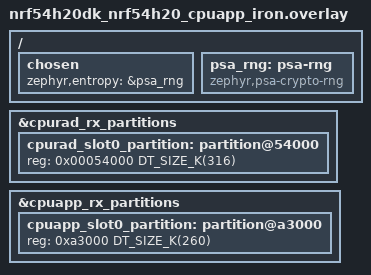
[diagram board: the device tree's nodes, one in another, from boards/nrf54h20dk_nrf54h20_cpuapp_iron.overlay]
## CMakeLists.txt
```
#
# Copyright (c) 2024 Nordic Semiconductor
#
# SPDX-License-Identifier: LicenseRef-Nordic-5-Clause
#

cmake_minimum_required(VERSION 3.20.0)

find_package(Zephyr REQUIRED HINTS $ENV{ZEPHYR_BASE})
project(channel_sound_ras_initiator)

FILE(GLOB app_sources src/*.c)
# NORDIC SDK APP START
target_sources(app PRIVATE
  ${app_sources}
)
# NORDIC SDK APP END
```

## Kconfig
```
#
# Copyright (c) 2024 Nordic Semiconductor ASA
#
# SPDX-License-Identifier: LicenseRef-Nordic-5-Clause
#

mainmenu "Nordic Channel Sounding RAS Initiator sample"

choice CS_TONE_ANTENNA_CONFIGURATION
	prompt "Tone antenna configuration selection"
	default CS_TONE_ANTENNA_CONFIGURATION_A1_B1
	help
	  Select the tone antenna configuration for channel sounding procedures.
	  The configuration determines how many antenna paths are used on each side
	  (initiator and reflector). The format is A<initiator_antennas>_B<reflector_antennas>.

config CS_TONE_ANTENNA_CONFIGURATION_A1_B1
	bool "A1_B1 (1 antenna path per side)"
	help
	  Use A1_B1 configuration with 1 antenna path on each side.
	  This requires BT_CTLR_SDC_CS_MAX_ANTENNA_PATHS >= 1.

config CS_TONE_ANTENNA_CONFIGURATION_A2_B1
	bool "A2_B1 (2 initiator, 1 reflector antenna paths)"
	help
	  Use A2_B1 configuration with 2 antenna paths on initiator side and
	  1 antenna path on reflector side.
	  This requires BT_CTLR_SDC_CS_MAX_ANTENNA_PATHS >= 2.

config CS_TONE_ANTENNA_CONFIGURATION_A3_B1
	bool "A3_B1 (3 initiator, 1 reflector antenna paths)"
	help
	  Use A3_B1 configuration with 3 antenna paths on initiator side and
	  1 antenna path on reflector side.
	  This requires BT_CTLR_SDC_CS_MAX_ANTENNA_PATHS >= 3.

config CS_TONE_ANTENNA_CONFIGURATION_A4_B1
	bool "A4_B1 (4 initiator, 1 reflector antenna paths)"
	help
	  Use A4_B1 configuration with 4 antenna paths on initiator side and
	  1 antenna path on reflector side.
	  This requires BT_CTLR_SDC_CS_MAX_ANTENNA_PATHS >= 4.

config CS_TONE_ANTENNA_CONFIGURATION_A1_B2
	bool "A1_B2 (1 initiator, 2 reflector antenna paths)"
	help
	  Use A1_B2 configuration with 1 antenna path on initiator side and
	  2 antenna paths on reflector side.
	  This requires BT_CTLR_SDC_CS_MAX_ANTENNA_PATHS >= 2.

config CS_TONE_ANTENNA_CONFIGURATION_A1_B3
	bool "A1_B3 (1 initiator, 3 reflector antenna paths)"
	help
	  Use A1_B3 configuration with 1 antenna path on initiator side and
	  3 antenna paths on reflector side.
	  This requires BT_CTLR_SDC_CS_MAX_ANTENNA_PATHS >= 3.

config CS_TONE_ANTENNA_CONFIGURATION_A1_B4
	bool "A1_B4 (1 initiator, 4 reflector antenna paths)"
	help
	  Use A1_B4 configuration with 1 antenna path on initiator side and
	  4 antenna paths on reflector side.
	  This requires BT_CTLR_SDC_CS_MAX_ANTENNA_PATHS >= 4.

config CS_TONE_ANTENNA_CONFIGURATION_A2_B2
	bool "A2_B2 (2 antenna paths per side)"
	help
	  Use A2_B2 configuration with 2 antenna paths on each side (4 total).
	  This requires BT_CTLR_SDC_CS_MAX_ANTENNA_PATHS >= 4.

endchoice

config CS_TONE_ANTENNA_CONFIGURATION_VALUE
	int
	default 0 if CS_TONE_ANTENNA_CONFIGURATION_A1_B1
	default 1 if CS_TONE_ANTENNA_CONFIGURATION_A2_B1
	default 2 if CS_TONE_ANTENNA_CONFIGURATION_A3_B1
	default 3 if CS_TONE_ANTENNA_CONFIGURATION_A4_B1
	default 4 if CS_TONE_ANTENNA_CONFIGURATION_A1_B2
	default 5 if CS_TONE_ANTENNA_CONFIGURATION_A1_B3
	default 6 if CS_TONE_ANTENNA_CONFIGURATION_A1_B4
	default 7 if CS_TONE_ANTENNA_CONFIGURATION_A2_B2
	help
	  Internal config value mapping to BT_LE_CS_TONE_ANTENNA_CONFIGURATION enum.
	  Not intended for direct use.

# Intermediate config: number of antenna paths required for the selected configuration
# This is the maximum number of antenna paths needed on either the initiator or reflector side
config CS_TONE_ANTENNA_CONFIGURATION_NUM_ANTENNA_PATHS
	int
	default 1 if CS_TONE_ANTENNA_CONFIGURATION_A1_B1
	default 2 if CS_TONE_ANTENNA_CONFIGURATION_A2_B1 || CS_TONE_ANTENNA_CONFIGURATION_A1_B2
	default 3 if CS_TONE_ANTENNA_CONFIGURATION_A3_B1 || CS_TONE_ANTENNA_CONFIGURATION_A1_B3
	default 4 if CS_TONE_ANTENNA_CONFIGURATION_A4_B1 || CS_TONE_ANTENNA_CONFIGURATION_A1_B4 || CS_TONE_ANTENNA_CONFIGURATION_A2_B2
	help
	  Number of antenna paths required for the selected tone antenna configuration.
	  This is calculated as the maximum number of antenna paths needed on either
	  the initiator or reflector side.

# Set default value for BT_CTLR_SDC_CS_MAX_ANTENNA_PATHS based on the required number of antenna paths
# This ensures the controller is configured with sufficient antenna paths for the selected configuration
if BT_CTLR_CHANNEL_SOUNDING
config BT_CTLR_SDC_CS_MAX_ANTENNA_PATHS
	default CS_TONE_ANTENNA_CONFIGURATION_NUM_ANTENNA_PATHS
endif

source "Kconfig.zephyr"
```

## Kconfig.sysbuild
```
#
# Copyright (c) 2025 Nordic Semiconductor
#
# SPDX-License-Identifier: LicenseRef-Nordic-5-Clause
#

source "share/sysbuild/Kconfig"

config NRF_DEFAULT_BLUETOOTH
	default y

config NETCORE_IPC_RADIO_BT_HCI_IPC
	default y
```

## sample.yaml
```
sample:
  description: Bluetooth Low Energy Channel Sounding Initiator with Ranging Service
    Requestor
  name: Bluetooth LE Channel Sounding Initiator with RREQ
tests:
  sample.bluetooth.channel_sounding_ras_initiator:
    sysbuild: true
    build_only: true
    integration_platforms:
      - nrf54h20dk/nrf54h20/cpuapp
      - nrf54l15dk/nrf54l15/cpuapp
    platform_allow:
      - nrf54l15dk/nrf54l05/cpuapp
      - nrf54l15dk/nrf54l10/cpuapp
      - nrf54l15dk/nrf54l15/cpuapp
      - nrf54h20dk/nrf54h20/cpuapp
      - nrf54lm20dk/nrf54lm20a/cpuapp
      - nrf54lv10dk/nrf54lv10a/cpuapp
      - nrf54lv10dk/nrf54lv10a/cpuapp/ns
    tags:
      - bluetooth
      - ci_build
      - sysbuild
```

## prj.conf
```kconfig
#
# Copyright (c) 2024 Nordic Semiconductor ASA
#
# SPDX-License-Identifier: LicenseRef-Nordic-5-Clause
#

CONFIG_NCS_SAMPLES_DEFAULTS=y
CONFIG_DK_LIBRARY=y

CONFIG_BT=y
CONFIG_BT_SMP=y
CONFIG_BT_CENTRAL=y
CONFIG_BT_MAX_CONN=1
CONFIG_BT_BONDABLE=n

CONFIG_BT_GATT_CLIENT=y
CONFIG_BT_GATT_DYNAMIC_DB=y

CONFIG_BT_CHANNEL_SOUNDING=y
CONFIG_BT_RAS=y
CONFIG_BT_RAS_RREQ=y

CONFIG_BT_SCAN=y
CONFIG_BT_SCAN_FILTER_ENABLE=y
CONFIG_BT_SCAN_UUID_CNT=1

# The Ranging Profile recommends a MTU of at least 247 octets.
CONFIG_BT_L2CAP_TX_MTU=498
CONFIG_BT_BUF_ACL_TX_SIZE=502
CONFIG_BT_BUF_ACL_RX_SIZE=502
CONFIG_BT_ATT_PREPARE_COUNT=3
CONFIG_BT_CTLR_DATA_LENGTH_MAX=251

# This reduces RAM usage. Additional RAM is needed to support optional
# features such as mode 3 or multiantenna. Change or remove these if
# using those features
CONFIG_BT_RAS_MODE_3_SUPPORTED=n
CONFIG_BT_RAS_MAX_ANTENNA_PATHS=1
CONFIG_BT_CTLR_SDC_CS_MAX_ANTENNA_PATHS=1
CONFIG_BT_CTLR_SDC_CS_NUM_ANTENNAS=1
CONFIG_BT_CTLR_SDC_CS_STEP_MODE3=n
CONFIG_BT_CTLR_SDC_CS_ROLE_INITIATOR_ONLY=y

# Disabling the CS Test command reduces flash usage
CONFIG_BT_CTLR_CHANNEL_SOUNDING_TEST=n

# This allows CS and ACL to use different PHYs
CONFIG_BT_TRANSMIT_POWER_CONTROL=y

# This improves the performance of floating-point operations
CONFIG_FPU=y
CONFIG_FPU_SHARING=y

CONFIG_CBPRINTF_FP_SUPPORT=y

CONFIG_BT_CS_DE=y
CONFIG_BT_CS_DE_512_NFFT=y
CONFIG_CS_TONE_ANTENNA_CONFIGURATION_A4_B1=y
```

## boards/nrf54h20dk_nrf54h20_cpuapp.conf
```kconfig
#
# Copyright (c) 2025 Nordic Semiconductor
#
# SPDX-License-Identifier: LicenseRef-Nordic-5-Clause
#

CONFIG_BT_RX_STACK_SIZE=2048

# Enable PSA RNG
CONFIG_PSA_CRYPTO_DRIVER_OBERON=n
CONFIG_PSA_SSF_CRYPTO_CLIENT=y
CONFIG_SSF_PSA_CRYPTO_SERVICE_ENABLED=y
CONFIG_MBEDTLS_PSA_CRYPTO_C=y
CONFIG_NRF_SECURITY=y
```

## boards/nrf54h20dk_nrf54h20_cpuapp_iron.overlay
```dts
/*
 * Copyright (c) 2025 Nordic Semiconductor ASA
 *
 * SPDX-License-Identifier: LicenseRef-Nordic-5-Clause
 */

/delete-node/ &cpuapp_slot0_partition;
/delete-node/ &cpurad_slot0_partition;

/* Allocate extra MRAM as 256K is not enough NVM for multiantenna CS.
 * The extra memory is taken from cpuapp below.
 */
&cpurad_rx_partitions {
	cpurad_slot0_partition: partition@54000 {
		reg = <0x00054000 DT_SIZE_K(316)>;
	};
};

/* Reduce cpuapp by 60K (default 320 - 60) */
&cpuapp_rx_partitions {
	cpuapp_slot0_partition: partition@a3000 {
		reg = <0xa3000 DT_SIZE_K(260)>;
	};
};

// Enable PSA RNG
/ {
	chosen {
		zephyr,entropy = &psa_rng;
	};

	psa_rng: psa-rng {
		compatible = "zephyr,psa-crypto-rng";
		status = "okay";
	};

	/delete-node/ prng;
};
```

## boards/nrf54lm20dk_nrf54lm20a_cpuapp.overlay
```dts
/*
 * Copyright (c) 2025 Nordic Semiconductor ASA
 *
 * SPDX-License-Identifier: LicenseRef-Nordic-5-Clause
 */

/ {
	cs_antenna_switch: cs-antenna-config {
		status = "okay";
		compatible = "nordic,bt-cs-antenna-switch";
		ant-gpios = <&gpio1 17 GPIO_ACTIVE_HIGH>,
			    <&gpio1 18 GPIO_ACTIVE_HIGH>,
			    <&gpio1 19 GPIO_ACTIVE_HIGH>,
			    <&gpio1 20 GPIO_ACTIVE_HIGH>;
		multiplexing-mode = <0>;
	};
};
```

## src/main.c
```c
/*
 * Copyright (c) 2024 Nordic Semiconductor ASA
 *
 * SPDX-License-Identifier: LicenseRef-Nordic-5-Clause
 */

/** @file
 *  @brief Channel Sounding Initiator with Ranging Requestor sample
 */

#include <math.h>
#include <stdlib.h>
#include <zephyr/kernel.h>
#include <zephyr/types.h>
#include <zephyr/sys/byteorder.h>
#include <zephyr/sys/reboot.h>
#include <zephyr/bluetooth/cs.h>
#include <zephyr/bluetooth/gatt.h>
#include <zephyr/bluetooth/conn.h>
#include <bluetooth/scan.h>
#include <bluetooth/services/ras.h>
#include <bluetooth/gatt_dm.h>
#include <bluetooth/cs_de.h>

#include <dk_buttons_and_leds.h>

#include <zephyr/logging/log.h>
LOG_MODULE_REGISTER(app_main, LOG_LEVEL_INF);

#define CON_STATUS_LED DK_LED1

#define CS_CONFIG_ID	       0
#define NUM_MODE_0_STEPS       3
#define PROCEDURE_COUNTER_NONE (-1)
#define DE_SLIDING_WINDOW_SIZE (9)
#define MAX_AP		       (CONFIG_BT_RAS_MAX_ANTENNA_PATHS)

#define LOCAL_PROCEDURE_MEM                                                                        \
	((BT_RAS_MAX_STEPS_PER_PROCEDURE * sizeof(struct bt_le_cs_subevent_step)) +                \
	 (BT_RAS_MAX_STEPS_PER_PROCEDURE * BT_RAS_MAX_STEP_DATA_LEN))

static K_SEM_DEFINE(sem_remote_capabilities_obtained, 0, 1);
static K_SEM_DEFINE(sem_config_created, 0, 1);
static K_SEM_DEFINE(sem_cs_security_enabled, 0, 1);
static K_SEM_DEFINE(sem_connected, 0, 1);
static K_SEM_DEFINE(sem_discovery_done, 0, 1);
static K_SEM_DEFINE(sem_mtu_exchange_done, 0, 1);
static K_SEM_DEFINE(sem_security, 0, 1);
static K_SEM_DEFINE(sem_ras_features, 0, 1);
static K_SEM_DEFINE(sem_local_steps, 1, 1);
static K_SEM_DEFINE(sem_distance_estimate_updated, 0, 1);

static K_MUTEX_DEFINE(distance_estimate_buffer_mutex);

static struct bt_conn *connection;
NET_BUF_SIMPLE_DEFINE_STATIC(latest_local_steps, LOCAL_PROCEDURE_MEM);
NET_BUF_SIMPLE_DEFINE_STATIC(latest_peer_steps, BT_RAS_PROCEDURE_MEM);
static int32_t most_recent_local_ranging_counter = PROCEDURE_COUNTER_NONE;
static int32_t dropped_ranging_counter = PROCEDURE_COUNTER_NONE;
static uint32_t ras_feature_bits;

static uint8_t buffer_index;
static uint8_t buffer_num_valid;
static cs_de_dist_estimates_t distance_estimate_buffer[MAX_AP][DE_SLIDING_WINDOW_SIZE];
static struct bt_conn_le_cs_config cs_config;

static void store_distance_estimates(cs_de_report_t *p_report)
{
	int lock_state = k_mutex_lock(&distance_estimate_buffer_mutex, K_FOREVER);

	__ASSERT_NO_MSG(lock_state == 0);

	for (uint8_t ap = 0; ap < p_report->n_ap; ap++) {
		memcpy(&distance_estimate_buffer[ap][buffer_index],
		       &p_report->distance_estimates[ap], sizeof(cs_de_dist_estimates_t));
	}

	buffer_index = (buffer_index + 1) % DE_SLIDING_WINDOW_SIZE;

	if (buffer_num_valid < DE_SLIDING_WINDOW_SIZE) {
		buffer_num_valid++;
	}

	k_mutex_unlock(&distance_estimate_buffer_mutex);
}

static int float_cmp(const void *a, const void *b)
{
	float fa = *(const float *)a;
	float fb = *(const float *)b;

	return (fa > fb) - (fa < fb);
}

static float median_inplace(int count, float *values)
{
	if (count == 0) {
		return NAN;
	}

	qsort(values, count, sizeof(float), float_cmp);

	if (count % 2 == 0) {
		return (values[count/2] + values[count/2 - 1]) / 2;
	} else {
		return values[count/2];
	}
}

static cs_de_dist_estimates_t get_distance(uint8_t ap)
{
	cs_de_dist_estimates_t averaged_result = {};
	uint8_t num_ifft = 0;
	uint8_t num_phase_slope = 0;
	uint8_t num_rtt = 0;

	static float temp_ifft[DE_SLIDING_WINDOW_SIZE];
	static float temp_phase_slope[DE_SLIDING_WINDOW_SIZE];
	static float temp_rtt[DE_SLIDING_WINDOW_SIZE];

	int lock_state = k_mutex_lock(&distance_estimate_buffer_mutex, K_FOREVER);

	__ASSERT_NO_MSG(lock_state == 0);

	for (uint8_t i = 0; i < buffer_num_valid; i++) {
		if (isfinite(distance_estimate_buffer[ap][i].ifft)) {
			temp_ifft[num_ifft] = distance_estimate_buffer[ap][i].ifft;
			num_ifft++;
		}
		if (isfinite(distance_estimate_buffer[ap][i].phase_slope)) {
			temp_phase_slope[num_phase_slope] =
				distance_estimate_buffer[ap][i].phase_slope;
			num_phase_slope++;
		}
		if (isfinite(distance_estimate_buffer[ap][i].rtt)) {
			temp_rtt[num_rtt] = distance_estimate_buffer[ap][i].rtt;
			num_rtt++;
		}
	}

	k_mutex_unlock(&distance_estimate_buffer_mutex);

	averaged_result.ifft = median_inplace(num_ifft, temp_ifft);
	averaged_result.phase_slope = median_inplace(num_phase_slope, temp_phase_slope);
	averaged_result.rtt = median_inplace(num_rtt, temp_rtt);

	return averaged_result;
}

static void ranging_data_cb(struct bt_conn *conn, uint16_t ranging_counter, int err)
{
	ARG_UNUSED(conn);

	if (err) {
		LOG_ERR("Error when receiving ranging data with ranging counter %d (err %d)",
			ranging_counter, err);
		return;
	}

	if (ranging_counter != most_recent_local_ranging_counter) {
		LOG_INF("Ranging data dropped as peer ranging counter doesn't match local ranging "
			"data counter. (peer: %u, local: %u)",
			ranging_counter, most_recent_local_ranging_counter);
		net_buf_simple_reset(&latest_local_steps);
		k_sem_give(&sem_local_steps);
		return;
	}

	LOG_DBG("Ranging data received for ranging counter %d", ranging_counter);

	if (latest_local_steps.len == 0) {
		LOG_WRN("All subevents in ranging counter %u were aborted",
			most_recent_local_ranging_counter);
		net_buf_simple_reset(&latest_local_steps);
		k_sem_give(&sem_local_steps);

		if (!(ras_feature_bits & RAS_FEAT_REALTIME_RD)) {
			net_buf_simple_reset(&latest_peer_steps);
		}
		return;
	}

	/* This struct is static to avoid putting it on the stack (it's very large) */
	static cs_de_report_t cs_de_report;

	cs_de_populate_report(&latest_local_steps, &latest_peer_steps, &cs_config, &cs_de_report);

	net_buf_simple_reset(&latest_local_steps);

	if (!(ras_feature_bits & RAS_FEAT_REALTIME_RD)) {
		net_buf_simple_reset(&latest_peer_steps);
	}

	k_sem_give(&sem_local_steps);

	cs_de_quality_t quality = cs_de_calc(&cs_de_report);

	if (quality == CS_DE_QUALITY_OK) {
		for (uint8_t ap = 0; ap < cs_de_report.n_ap; ap++) {
			if (cs_de_report.tone_quality[ap] == CS_DE_TONE_QUALITY_OK) {
				store_distance_estimates(&cs_de_report);
			}
		}
		k_sem_give(&sem_distance_estimate_updated);
	}
}

static void subevent_result_cb(struct bt_conn *conn, struct bt_conn_le_cs_subevent_result *result)
{
	if (dropped_ranging_counter == result->header.procedure_counter) {
		return;
	}

	if (most_recent_local_ranging_counter
		!= bt_ras_rreq_get_ranging_counter(result->header.procedure_counter)) {
		int sem_state = k_sem_take(&sem_local_steps, K_NO_WAIT);

		if (sem_state < 0) {
			dropped_ranging_counter = result->header.procedure_counter;
			LOG_INF("Dropped subevent results. Waiting for ranging data from peer.");
			return;
		}

		most_recent_local_ranging_counter =
			bt_ras_rreq_get_ranging_counter(result->header.procedure_counter);
	}

	if (result->header.subevent_done_status == BT_CONN_LE_CS_SUBEVENT_ABORTED) {
		/* The steps from this subevent will not be used. */
	} else if (result->step_data_buf) {
		if (result->step_data_buf->len <= net_buf_simple_tailroom(&latest_local_steps)) {
			uint16_t len = result->step_data_buf->len;
			uint8_t *step_data = net_buf_simple_pull_mem(result->step_data_buf, len);

			net_buf_simple_add_mem(&latest_local_steps, step_data, len);
		} else {
			LOG_ERR("Not enough memory to store step data. (%d > %d)",
				latest_local_steps.len + result->step_data_buf->len,
				latest_local_steps.size);
			net_buf_simple_reset(&latest_local_steps);
			dropped_ranging_counter = result->header.procedure_counter;
			return;
		}
	}

	dropped_ranging_counter = PROCEDURE_COUNTER_NONE;

	if (result->header.procedure_done_status == BT_CONN_LE_CS_PROCEDURE_COMPLETE) {
		most_recent_local_ranging_counter =
			bt_ras_rreq_get_ranging_counter(result->header.procedure_counter);
	} else if (result->header.procedure_done_status == BT_CONN_LE_CS_PROCEDURE_ABORTED) {
		LOG_WRN("Procedure %u aborted", result->header.procedure_counter);
		net_buf_simple_reset(&latest_local_steps);
		k_sem_give(&sem_local_steps);
	}
}

static void ranging_data_ready_cb(struct bt_conn *conn, uint16_t ranging_counter)
{
	LOG_DBG("Ranging data ready %i", ranging_counter);

	if (ranging_counter == most_recent_local_ranging_counter) {
		int err = bt_ras_rreq_cp_get_ranging_data(connection, &latest_peer_steps,
							  ranging_counter,
							  ranging_data_cb);
		if (err) {
			LOG_ERR("Get ranging data failed (err %d)", err);
			net_buf_simple_reset(&latest_local_steps);
			net_buf_simple_reset(&latest_peer_steps);
			k_sem_give(&sem_local_steps);
		}
	}
}

static void ranging_data_overwritten_cb(struct bt_conn *conn, uint16_t ranging_counter)
{
	LOG_INF("Ranging data overwritten %i", ranging_counter);
}

static void mtu_exchange_cb(struct bt_conn *conn, uint8_t err,
			    struct bt_gatt_exchange_params *params)
{
	if (err) {
		LOG_ERR("MTU exchange failed (err %d)", err);
		return;
	}

	LOG_INF("MTU exchange success (%u)", bt_gatt_get_mtu(conn));
	k_sem_give(&sem_mtu_exchange_done);
}

static void discovery_completed_cb(struct bt_gatt_dm *dm, void *context)
{
	int err;

	LOG_INF("The discovery procedure succeeded");

	struct bt_conn *conn = bt_gatt_dm_conn_get(dm);

	bt_gatt_dm_data_print(dm);

	err = bt_ras_rreq_alloc_and_assign_handles(dm, conn);
	if (err) {
		LOG_ERR("RAS RREQ alloc init failed (err %d)", err);
	}

	err = bt_gatt_dm_data_release(dm);
	if (err) {
		LOG_ERR("Could not release the discovery data (err %d)", err);
	}

	k_sem_give(&sem_discovery_done);
}

static void discovery_service_not_found_cb(struct bt_conn *conn, void *context)
{
	LOG_INF("The service could not be found during the discovery, disconnecting");
	bt_conn_disconnect(connection, BT_HCI_ERR_REMOTE_USER_TERM_CONN);
}

static void discovery_error_found_cb(struct bt_conn *conn, int err, void *context)
{
	LOG_INF("The discovery procedure failed (err %d)", err);
	bt_conn_disconnect(connection, BT_HCI_ERR_REMOTE_USER_TERM_CONN);
}

static struct bt_gatt_dm_cb discovery_cb = {
	.completed = discovery_completed_cb,
	.service_not_found = discovery_service_not_found_cb,
	.error_found = discovery_error_found_cb,
};

static void security_changed(struct bt_conn *conn, bt_security_t level, enum bt_security_err err)
{
	char addr[BT_ADDR_LE_STR_LEN];

	bt_addr_le_to_str(bt_conn_get_dst(conn), addr, sizeof(addr));

	if (err) {
		LOG_ERR("Security failed: %s level %u err %d %s", addr, level, err,
			bt_security_err_to_str(err));
		return;
	}

	LOG_INF("Security changed: %s level %u", addr, level);
	k_sem_give(&sem_security);
}

static bool le_param_req(struct bt_conn *conn, struct bt_le_conn_param *param)
{
	/* Ignore peer parameter preferences. */
	return false;
}

static void connected_cb(struct bt_conn *conn, uint8_t err)
{
	char addr[BT_ADDR_LE_STR_LEN];

	(void)bt_addr_le_to_str(bt_conn_get_dst(conn), addr, sizeof(addr));
	LOG_INF("Connected to %s (err 0x%02X)", addr, err);

	if (err) {
		bt_conn_unref(conn);
		connection = NULL;
	} else {
		connection = bt_conn_ref(conn);

		k_sem_give(&sem_connected);

		dk_set_led_on(CON_STATUS_LED);
	}
}

static void disconnected_cb(struct bt_conn *conn, uint8_t reason)
{
	LOG_INF("Disconnected (reason 0x%02X)", reason);

	bt_conn_unref(conn);
	connection = NULL;
	dk_set_led_off(CON_STATUS_LED);

	sys_reboot(SYS_REBOOT_COLD);
}

static void remote_capabilities_cb(struct bt_conn *conn,
				   uint8_t status,
				   struct bt_conn_le_cs_capabilities *params)
{
	ARG_UNUSED(conn);
	ARG_UNUSED(params);

	if (status == BT_HCI_ERR_SUCCESS) {
		LOG_INF("CS capability exchange completed.");
		k_sem_give(&sem_remote_capabilities_obtained);
	} else {
		LOG_WRN("CS capability exchange failed. (HCI status 0x%02x)", status);
	}
}

static void config_create_cb(struct bt_conn *conn, uint8_t status,
			     struct bt_conn_le_cs_config *config)
{
	ARG_UNUSED(conn);

	if (status == BT_HCI_ERR_SUCCESS) {
		cs_config = *config;

		const char *mode_str[5] = {"Unused", "1 (RTT)", "2 (PBR)", "3 (RTT + PBR)",
					   "Invalid"};
		const char *role_str[3] = {"Initiator", "Reflector", "Invalid"};
		const char *rtt_type_str[8] = {
			"AA only",	 "32-bit sounding", "96-bit sounding", "32-bit random",
			"64-bit random", "96-bit random",   "128-bit random",  "Invalid"};
		const char *phy_str[4] = {"Invalid", "LE 1M PHY", "LE 2M PHY", "LE 2M 2BT PHY"};
		const char *chsel_type_str[3] = {"Algorithm #3b", "Algorithm #3c", "Invalid"};
		const char *ch3c_shape_str[3] = {"Hat shape", "X shape", "Invalid"};

		uint8_t mode_idx = config->mode > 0 && config->mode < 4 ? config->mode : 4;
		uint8_t role_idx = MIN(config->role, 2);
		uint8_t rtt_type_idx = MIN(config->rtt_type, 7);
		uint8_t phy_idx = config->cs_sync_phy > 0 && config->cs_sync_phy < 4
					  ? config->cs_sync_phy
					  : 0;
		uint8_t chsel_type_idx = MIN(config->channel_selection_type, 2);
		uint8_t ch3c_shape_idx = MIN(config->ch3c_shape, 2);

		LOG_INF("CS config creation complete.\n"
			" - id: %u\n"
			" - mode: %s\n"
			" - min_main_mode_steps: %u\n"
			" - max_main_mode_steps: %u\n"
			" - main_mode_repetition: %u\n"
			" - mode_0_steps: %u\n"
			" - role: %s\n"
			" - rtt_type: %s\n"
			" - cs_sync_phy: %s\n"
			" - channel_map_repetition: %u\n"
			" - channel_selection_type: %s\n"
			" - ch3c_shape: %s\n"
			" - ch3c_jump: %u\n"
			" - t_ip1_time_us: %u\n"
			" - t_ip2_time_us: %u\n"
			" - t_fcs_time_us: %u\n"
			" - t_pm_time_us: %u\n"
			" - channel_map: 0x%08X%08X%04X\n",
			config->id, mode_str[mode_idx],
			config->min_main_mode_steps, config->max_main_mode_steps,
			config->main_mode_repetition, config->mode_0_steps, role_str[role_idx],
			rtt_type_str[rtt_type_idx], phy_str[phy_idx],
			config->channel_map_repetition, chsel_type_str[chsel_type_idx],
			ch3c_shape_str[ch3c_shape_idx], config->ch3c_jump, config->t_ip1_time_us,
			config->t_ip2_time_us, config->t_fcs_time_us, config->t_pm_time_us,
			sys_get_le32(&config->channel_map[6]),
			sys_get_le32(&config->channel_map[2]),
			sys_get_le16(&config->channel_map[0]));

		k_sem_give(&sem_config_created);
	} else {
		LOG_WRN("CS config creation failed. (HCI status 0x%02x)", status);
	}
}

static void security_enable_cb(struct bt_conn *conn, uint8_t status)
{
	ARG_UNUSED(conn);

	if (status == BT_HCI_ERR_SUCCESS) {
		LOG_INF("CS security enabled.");
		k_sem_give(&sem_cs_security_enabled);
	} else {
		LOG_WRN("CS security enable failed. (HCI status 0x%02x)", status);
	}
}

static void procedure_enable_cb(struct bt_conn *conn,
				uint8_t status,
				struct bt_conn_le_cs_procedure_enable_complete *params)
{
	ARG_UNUSED(conn);

	if (status == BT_HCI_ERR_SUCCESS) {
		if (params->state == 1) {
			LOG_INF("CS procedures enabled:\n"
				" - config ID: %u\n"
				" - antenna configuration index: %u\n"
				" - TX power: %d dbm\n"
				" - subevent length: %u us\n"
				" - subevents per event: %u\n"
				" - subevent interval: %u\n"
				" - event interval: %u\n"
				" - procedure interval: %u\n"
				" - procedure count: %u\n"
				" - maximum procedure length: %u",
				params->config_id, params->tone_antenna_config_selection,
				params->selected_tx_power, params->subevent_len,
				params->subevents_per_event, params->subevent_interval,
				params->event_interval, params->procedure_interval,
				params->procedure_count, params->max_procedure_len);
		} else {
			LOG_INF("CS procedures disabled.");
		}
	} else {
		LOG_WRN("CS procedures enable failed. (HCI status 0x%02x)", status);
	}
}

void ras_features_read_cb(struct bt_conn *conn, uint32_t feature_bits, int err)
{
	if (err) {
		LOG_WRN("Error while reading RAS feature bits (err %d)", err);
	} else {
		LOG_INF("Read RAS feature bits: 0x%x", feature_bits);
		ras_feature_bits = feature_bits;
	}

	k_sem_give(&sem_ras_features);
}

static void scan_filter_match(struct bt_scan_device_info *device_info,
			      struct bt_scan_filter_match *filter_match, bool connectable)
{
	char addr[BT_ADDR_LE_STR_LEN];

	bt_addr_le_to_str(device_info->recv_info->addr, addr, sizeof(addr));

	LOG_INF("Filters matched. Address: %s connectable: %d", addr, connectable);
}

static void scan_connecting_error(struct bt_scan_device_info *device_info)
{
	int err;

	LOG_INF("Connecting failed, restarting scanning");

	err = bt_scan_start(BT_SCAN_TYPE_SCAN_PASSIVE);
	if (err) {
		LOG_ERR("Failed to restart scanning (err %i)", err);
		return;
	}
}

static void scan_connecting(struct bt_scan_device_info *device_info, struct bt_conn *conn)
{
	LOG_INF("Connecting");
}

BT_SCAN_CB_INIT(scan_cb, scan_filter_match, NULL, scan_connecting_error, scan_connecting);

static int scan_init(void)
{
	int err;

	struct bt_scan_init_param param = {
		.scan_param = NULL,
		.conn_param = BT_LE_CONN_PARAM(0x10, 0x10, 0, BT_GAP_MS_TO_CONN_TIMEOUT(4000)),
		.connect_if_match = 1};

	bt_scan_init(&param);
	bt_scan_cb_register(&scan_cb);

	err = bt_scan_filter_add(BT_SCAN_FILTER_TYPE_UUID, BT_UUID_RANGING_SERVICE);
	if (err) {
		LOG_ERR("Scanning filters cannot be set (err %d)", err);
		return err;
	}

	err = bt_scan_filter_enable(BT_SCAN_UUID_FILTER, false);
	if (err) {
		LOG_ERR("Filters cannot be turned on (err %d)", err);
		return err;
	}

	return 0;
}

BT_CONN_CB_DEFINE(conn_cb) = {
	.connected = connected_cb,
	.disconnected = disconnected_cb,
	.le_param_req = le_param_req,
	.security_changed = security_changed,
	.le_cs_read_remote_capabilities_complete = remote_capabilities_cb,
	.le_cs_config_complete = config_create_cb,
	.le_cs_security_enable_complete = security_enable_cb,
	.le_cs_procedure_enable_complete = procedure_enable_cb,
	.le_cs_subevent_data_available = subevent_result_cb,
};

int main(void)
{
	int err;

	LOG_INF("Starting Channel Sounding Initiator Sample");

	dk_leds_init();

	err = bt_enable(NULL);
	if (err) {
		LOG_ERR("Bluetooth init failed (err %d)", err);
		return 0;
	}

	err = scan_init();
	if (err) {
		LOG_ERR("Scan init failed (err %d)", err);
		return 0;
	}

	err = bt_scan_start(BT_SCAN_TYPE_SCAN_PASSIVE);
	if (err) {
		LOG_ERR("Scanning failed to start (err %i)", err);
		return 0;
	}

	k_sem_take(&sem_connected, K_FOREVER);

	err = bt_conn_set_security(connection, BT_SECURITY_L2);
	if (err) {
		LOG_ERR("Failed to encrypt connection (err %d)", err);
		return 0;
	}

	k_sem_take(&sem_security, K_FOREVER);

	static struct bt_gatt_exchange_params mtu_exchange_params = {.func = mtu_exchange_cb};

	bt_gatt_exchange_mtu(connection, &mtu_exchange_params);

	k_sem_take(&sem_mtu_exchange_done, K_FOREVER);

	err = bt_gatt_dm_start(connection, BT_UUID_RANGING_SERVICE, &discovery_cb, NULL);
	if (err) {
		LOG_ERR("Discovery failed (err %d)", err);
		return 0;
	}

	k_sem_take(&sem_discovery_done, K_FOREVER);

	const struct bt_le_cs_set_default_settings_param default_settings = {
		.enable_initiator_role = true,
		.enable_reflector_role = false,
		.cs_sync_antenna_selection = BT_LE_CS_ANTENNA_SELECTION_OPT_REPETITIVE,
		.max_tx_power = BT_HCI_OP_LE_CS_MAX_MAX_TX_POWER,
	};

	err = bt_le_cs_set_default_settings(connection, &default_settings);
	if (err) {
		LOG_ERR("Failed to configure default CS settings (err %d)", err);
		return 0;
	}

	err = bt_ras_rreq_read_features(connection, ras_features_read_cb);
	if (err) {
		LOG_ERR("Could not get RAS features from peer (err %d)", err);
		return 0;
	}

	k_sem_take(&sem_ras_features, K_FOREVER);

	const bool realtime_rd = ras_feature_bits & RAS_FEAT_REALTIME_RD;

	if (realtime_rd) {
		err = bt_ras_rreq_realtime_rd_subscribe(connection,
							&latest_peer_steps,
							ranging_data_cb);
		if (err) {
			LOG_ERR("RAS RREQ Real-time ranging data subscribe failed (err %d)", err);
			return 0;
		}
	} else {
		err = bt_ras_rreq_rd_overwritten_subscribe(connection, ranging_data_overwritten_cb);
		if (err) {
			LOG_ERR("RAS RREQ ranging data overwritten subscribe failed (err %d)", err);
			return 0;
		}

		err = bt_ras_rreq_rd_ready_subscribe(connection, ranging_data_ready_cb);
		if (err) {
			LOG_ERR("RAS RREQ ranging data ready subscribe failed (err %d)", err);
			return 0;
		}

		err = bt_ras_rreq_on_demand_rd_subscribe(connection);
		if (err) {
			LOG_ERR("RAS RREQ On-demand ranging data subscribe failed (err %d)", err);
			return 0;
		}

		err = bt_ras_rreq_cp_subscribe(connection);
		if (err) {
			LOG_ERR("RAS RREQ CP subscribe failed (err %d)", err);
			return 0;
		}
	}

	err = bt_le_cs_read_remote_supported_capabilities(connection);
	if (err) {
		LOG_ERR("Failed to exchange CS capabilities (err %d)", err);
		return 0;
	}

	k_sem_take(&sem_remote_capabilities_obtained, K_FOREVER);

	struct bt_le_cs_create_config_params config_params = {
		.id = CS_CONFIG_ID,
		.mode = BT_CONN_LE_CS_MAIN_MODE_2_SUB_MODE_1,
		.min_main_mode_steps = 2,
		.max_main_mode_steps = 5,
		.main_mode_repetition = 0,
		.mode_0_steps = NUM_MODE_0_STEPS,
		.role = BT_CONN_LE_CS_ROLE_INITIATOR,
		.rtt_type = BT_CONN_LE_CS_RTT_TYPE_AA_ONLY,
		.cs_sync_phy = BT_CONN_LE_CS_SYNC_1M_PHY,
		.channel_map_repetition = 1,
		.channel_selection_type = BT_CONN_LE_CS_CHSEL_TYPE_3B,
		.ch3c_shape = BT_CONN_LE_CS_CH3C_SHAPE_HAT,
		.ch3c_jump = 2,
	};

	bt_le_cs_set_valid_chmap_bits(config_params.channel_map);

	err = bt_le_cs_create_config(connection, &config_params,
				     BT_LE_CS_CREATE_CONFIG_CONTEXT_LOCAL_AND_REMOTE);
	if (err) {
		LOG_ERR("Failed to create CS config (err %d)", err);
		return 0;
	}

	k_sem_take(&sem_config_created, K_FOREVER);

	err = bt_le_cs_security_enable(connection);
	if (err) {
		LOG_ERR("Failed to start CS Security (err %d)", err);
		return 0;
	}

	k_sem_take(&sem_cs_security_enabled, K_FOREVER);

	const struct bt_le_cs_set_procedure_parameters_param procedure_params = {
		.config_id = CS_CONFIG_ID,
		.max_procedure_len = 1000,
		.min_procedure_interval = realtime_rd ? 5 : 10,
		.max_procedure_interval = realtime_rd ? 5 : 10,
		.max_procedure_count = 0,
		.min_subevent_len = 16000,
		.max_subevent_len = 16000,
		.tone_antenna_config_selection = BT_LE_CS_TONE_ANTENNA_CONFIGURATION_A1_B1,
		.phy = BT_LE_CS_PROCEDURE_PHY_2M,
		.tx_power_delta = 0x80,
		.preferred_peer_antenna = BT_LE_CS_PROCEDURE_PREFERRED_PEER_ANTENNA_1,
		.snr_control_initiator = BT_LE_CS_SNR_CONTROL_NOT_USED,
		.snr_control_reflector = BT_LE_CS_SNR_CONTROL_NOT_USED,
	};

	err = bt_le_cs_set_procedure_parameters(connection, &procedure_params);
	if (err) {
		LOG_ERR("Failed to set procedure parameters (err %d)", err);
		return 0;
	}

	struct bt_le_cs_procedure_enable_param params = {
		.config_id = CS_CONFIG_ID,
		.enable = 1,
	};

	err = bt_le_cs_procedure_enable(connection, &params);
	if (err) {
		LOG_ERR("Failed to enable CS procedures (err %d)", err);
		return 0;
	}

	while (true) {
		k_sem_take(&sem_distance_estimate_updated, K_FOREVER);
		if (buffer_num_valid != 0) {
			for (uint8_t ap = 0; ap < MAX_AP; ap++) {
				cs_de_dist_estimates_t distance_on_ap = get_distance(ap);

				LOG_INF("Latest distance estimates on antenna path %u: ifft: %.2f, "
					"phase_slope: %.2f, rtt: %.2f meters",
					ap, (double)distance_on_ap.ifft,
					(double)distance_on_ap.phase_slope,
					(double)distance_on_ap.rtt);
			}
		}
	}

	return 0;
}
```

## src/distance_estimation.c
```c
/*
 * Copyright (c) 2024 Nordic Semiconductor ASA
 *
 * SPDX-License-Identifier: LicenseRef-Nordic-5-Clause
 */

/** @file
 *  @brief Channel Sounding distance estimation for Ranging Requestor
 */

#include "zephyr/bluetooth/hci_types.h"
#include <math.h>
#include <zephyr/bluetooth/cs.h>
#include <bluetooth/services/ras.h>

#include <zephyr/logging/log.h>
LOG_MODULE_DECLARE(app_main, LOG_LEVEL_INF);

#define CS_FREQUENCY_MHZ(ch)	(2402u + 1u * (ch))
#define CS_FREQUENCY_HZ(ch)	(CS_FREQUENCY_MHZ(ch) * 1000000.0f)
#define SPEED_OF_LIGHT_M_PER_S	(299792458.0f)
#define SPEED_OF_LIGHT_NM_PER_S (SPEED_OF_LIGHT_M_PER_S / 1000000000.0f)
#define PI			3.14159265358979323846f
#define MAX_NUM_RTT_SAMPLES		256
#define MAX_NUM_IQ_SAMPLES		256 * CONFIG_BT_RAS_MAX_ANTENNA_PATHS

struct iq_sample_and_channel {
	bool failed;
	uint8_t channel;
	uint8_t antenna_path;
	struct bt_le_cs_iq_sample local_iq_sample;
	struct bt_le_cs_iq_sample peer_iq_sample;
};

struct rtt_timing {
	bool failed;
	int16_t toa_tod_initiator;
	int16_t tod_toa_reflector;
};

static struct iq_sample_and_channel iq_sample_channel_data[MAX_NUM_IQ_SAMPLES];
static struct rtt_timing rtt_timing_data[MAX_NUM_RTT_SAMPLES];

struct processing_context {
	uint16_t rtt_timing_data_index;
	uint16_t iq_sample_channel_data_index;
	uint8_t n_ap;
	enum bt_conn_le_cs_role role;
};

static void calc_complex_product(int32_t z_a_real, int32_t z_a_imag, int32_t z_b_real,
				 int32_t z_b_imag, int32_t *z_out_real, int32_t *z_out_imag)
{
	*z_out_real = z_a_real * z_b_real - z_a_imag * z_b_imag;
	*z_out_imag = z_a_real * z_b_imag + z_a_imag * z_b_real;
}

static float linear_regression(float *x_values, float *y_values, uint8_t n_samples)
{
	if (n_samples == 0) {
		return 0.0;
	}

	/* Estimates b in y = a + b x */

	float y_mean = 0.0;
	float x_mean = 0.0;

	for (uint8_t i = 0; i < n_samples; i++) {
		y_mean += (y_values[i] - y_mean) / (i + 1);
		x_mean += (x_values[i] - x_mean) / (i + 1);
	}

	float b_est_upper = 0.0;
	float b_est_lower = 0.0;

	for (uint8_t i = 0; i < n_samples; i++) {
		b_est_upper += (x_values[i] - x_mean) * (y_values[i] - y_mean);
		b_est_lower += (x_values[i] - x_mean) * (x_values[i] - x_mean);
	}

	return b_est_upper / b_est_lower;
}

static void bubblesort_2(float *array1, float *array2, uint16_t len)
{
	bool swapped;
	float temp;

	for (uint16_t i = 0; i < len - 1; i++) {
		swapped = false;
		for (uint16_t j = 0; j < len - i - 1; j++) {
			if (array1[j] > array1[j + 1]) {
				temp = array1[j];
				array1[j] = array1[j + 1];
				array1[j + 1] = temp;
				temp = array2[j];
				array2[j] = array2[j + 1];
				array2[j + 1] = temp;
				swapped = true;
			}
		}

		if (!swapped) {
			break;
		}
	}
}

static float estimate_distance_using_phase_slope(struct iq_sample_and_channel *data,
						 uint8_t len,
						 uint8_t ant_path,
						 uint8_t *samples_cnt)
{
	int32_t combined_i;
	int32_t combined_q;
	uint16_t num_angles = 0;
	static float theta[MAX_NUM_IQ_SAMPLES];
	static float frequencies[MAX_NUM_IQ_SAMPLES];

	for (uint8_t i = 0; i < len; i++) {
		if (!data[i].failed && data[i].antenna_path == ant_path) {
			calc_complex_product(data[i].local_iq_sample.i, data[i].local_iq_sample.q,
					     data[i].peer_iq_sample.i, data[i].peer_iq_sample.q,
					     &combined_i, &combined_q);

			theta[num_angles] = atan2(1.0 * combined_q, 1.0 * combined_i);
			frequencies[num_angles] = 1.0 * CS_FREQUENCY_MHZ(data[i].channel);
			num_angles++;
			*samples_cnt += 1;
		}
	}

	if (num_angles < 2) {
		return 0.0;
	}

	/* Sort phases by tone frequency */
	bubblesort_2(frequencies, theta, num_angles);

	/* One-dimensional phase unwrapping */
	for (uint8_t i = 1; i < num_angles; i++) {
		float difference = theta[i] - theta[i - 1];

		if (difference > PI) {
			for (uint8_t j = i; j < num_angles; j++) {
				theta[j] -= 2.0f * PI;
			}
		} else if (difference < -PI) {
			for (uint8_t j = i; j < num_angles; j++) {
				theta[j] += 2.0f * PI;
			}
		}
	}

	float phase_slope = linear_regression(frequencies, theta, num_angles);

	float distance = -phase_slope * (SPEED_OF_LIGHT_M_PER_S / (4 * PI));

	return distance / 1000000.0f; /* Scale to meters. */
}

static float estimate_distance_using_time_of_flight(uint8_t n_samples)
{
	float tof;
	float tof_mean = 0.0;

	/* Cumulative Moving Average */
	for (uint8_t i = 0; i < n_samples; i++) {
		if (!rtt_timing_data[i].failed) {
			tof = (rtt_timing_data[i].toa_tod_initiator -
			       rtt_timing_data[i].tod_toa_reflector) /
			      2;
			tof_mean += (tof - tof_mean) / (i + 1);
		}
	}

	float tof_mean_ns = tof_mean / 2.0f;

	return tof_mean_ns * SPEED_OF_LIGHT_NM_PER_S;
}

static void process_tone_info_data(struct processing_context *context,
			      struct bt_hci_le_cs_step_data_tone_info local_tone_info[],
			      struct bt_hci_le_cs_step_data_tone_info peer_tone_info[],
			      uint8_t channel, uint8_t antenna_permutation_index)
{
	for (uint8_t i = 0; i < (context->n_ap + 1); i++) {
		if (local_tone_info[i].extension_indicator != BT_HCI_LE_CS_NOT_TONE_EXT_SLOT ||
		    peer_tone_info[i].extension_indicator != BT_HCI_LE_CS_NOT_TONE_EXT_SLOT) {
			continue;
		}

		if (context->iq_sample_channel_data_index >= MAX_NUM_IQ_SAMPLES) {
			LOG_WRN("More IQ samples than size of iq_sample_channel_data array");
			return;
		}

		int antenna_path = bt_le_cs_get_antenna_path(context->n_ap,
							     antenna_permutation_index,
							     i);
		if (antenna_path < 0) {
			LOG_WRN("Invalid antenna path");
			return;
		}

		iq_sample_channel_data[context->iq_sample_channel_data_index].channel = channel;
		iq_sample_channel_data[context->iq_sample_channel_data_index].antenna_path =
			(uint8_t)antenna_path;
		iq_sample_channel_data[context->iq_sample_channel_data_index].local_iq_sample =
			bt_le_cs_parse_pct(local_tone_info[i].phase_correction_term);
		iq_sample_channel_data[context->iq_sample_channel_data_index].peer_iq_sample =
			bt_le_cs_parse_pct(peer_tone_info[i].phase_correction_term);

		if (local_tone_info[i].quality_indicator == BT_HCI_LE_CS_TONE_QUALITY_LOW ||
		    local_tone_info[i].quality_indicator == BT_HCI_LE_CS_TONE_QUALITY_UNAVAILABLE ||
		    peer_tone_info[i].quality_indicator == BT_HCI_LE_CS_TONE_QUALITY_LOW ||
		    peer_tone_info[i].quality_indicator == BT_HCI_LE_CS_TONE_QUALITY_UNAVAILABLE) {
			iq_sample_channel_data[context->iq_sample_channel_data_index].failed = true;
		}

		context->iq_sample_channel_data_index++;
	}
}

static void process_rtt_timing_data(struct processing_context *context,
			       struct bt_hci_le_cs_step_data_mode_1 *local_rtt_data,
			       struct bt_hci_le_cs_step_data_mode_1 *peer_rtt_data)
{
	if (context->rtt_timing_data_index >= MAX_NUM_RTT_SAMPLES) {
		LOG_WRN("More RTT samples processed than size of rtt_timing_data array");
		return;
	}

	if (local_rtt_data->packet_quality_aa_check !=
		    BT_HCI_LE_CS_PACKET_QUALITY_AA_CHECK_SUCCESSFUL ||
	    local_rtt_data->packet_rssi == BT_HCI_LE_CS_PACKET_RSSI_NOT_AVAILABLE ||
	    local_rtt_data->tod_toa_reflector == BT_HCI_LE_CS_TIME_DIFFERENCE_NOT_AVAILABLE ||
	    peer_rtt_data->packet_quality_aa_check !=
		    BT_HCI_LE_CS_PACKET_QUALITY_AA_CHECK_SUCCESSFUL ||
	    peer_rtt_data->packet_rssi == BT_HCI_LE_CS_PACKET_RSSI_NOT_AVAILABLE ||
	    peer_rtt_data->tod_toa_reflector == BT_HCI_LE_CS_TIME_DIFFERENCE_NOT_AVAILABLE) {
		rtt_timing_data[context->rtt_timing_data_index].failed = true;
	}

	if (context->role == BT_CONN_LE_CS_ROLE_INITIATOR) {
		rtt_timing_data[context->rtt_timing_data_index].toa_tod_initiator =
			local_rtt_data->toa_tod_initiator;
		rtt_timing_data[context->rtt_timing_data_index].tod_toa_reflector =
			peer_rtt_data->tod_toa_reflector;
	} else if (context->role == BT_CONN_LE_CS_ROLE_REFLECTOR) {
		rtt_timing_data[context->rtt_timing_data_index].tod_toa_reflector =
			local_rtt_data->tod_toa_reflector;
		rtt_timing_data[context->rtt_timing_data_index].toa_tod_initiator =
			peer_rtt_data->toa_tod_initiator;
	}

	context->rtt_timing_data_index++;
}

static bool process_step_data(struct bt_le_cs_subevent_step *local_step,
			      struct bt_le_cs_subevent_step *peer_step, void *user_data)
{
	struct processing_context *context = (struct processing_context *)user_data;

	if (local_step->mode == BT_CONN_LE_CS_MAIN_MODE_2) {
		struct bt_hci_le_cs_step_data_mode_2 *local_step_data =
			(struct bt_hci_le_cs_step_data_mode_2 *)local_step->data;
		struct bt_hci_le_cs_step_data_mode_2 *peer_step_data =
			(struct bt_hci_le_cs_step_data_mode_2 *)peer_step->data;

		process_tone_info_data(context, local_step_data->tone_info,
				       peer_step_data->tone_info, local_step->channel,
				       local_step_data->antenna_permutation_index);

	} else if (local_step->mode == BT_HCI_OP_LE_CS_MAIN_MODE_1) {
		struct bt_hci_le_cs_step_data_mode_1 *local_step_data =
			(struct bt_hci_le_cs_step_data_mode_1 *)local_step->data;
		struct bt_hci_le_cs_step_data_mode_1 *peer_step_data =
			(struct bt_hci_le_cs_step_data_mode_1 *)peer_step->data;

		process_rtt_timing_data(context, local_step_data, peer_step_data);

	} else if (local_step->mode == BT_HCI_OP_LE_CS_MAIN_MODE_3) {
		struct bt_hci_le_cs_step_data_mode_3 *local_step_data =
			(struct bt_hci_le_cs_step_data_mode_3 *)local_step->data;
		struct bt_hci_le_cs_step_data_mode_3 *peer_step_data =
			(struct bt_hci_le_cs_step_data_mode_3 *)peer_step->data;

		process_rtt_timing_data(context,
					(struct bt_hci_le_cs_step_data_mode_1 *)local_step_data,
					(struct bt_hci_le_cs_step_data_mode_1 *)peer_step_data);

		process_tone_info_data(context, local_step_data->tone_info,
				       peer_step_data->tone_info, local_step->channel,
				       local_step_data->antenna_permutation_index);
	}

	return true;
}

void estimate_distance(struct net_buf_simple *local_steps, struct net_buf_simple *peer_steps,
		       uint8_t n_ap, enum bt_conn_le_cs_role role)
{
	bool distance_measurement_failed = true;
	struct processing_context context = {
		.rtt_timing_data_index = 0,
		.iq_sample_channel_data_index = 0,
		.n_ap = n_ap,
		.role = role,
	};

	memset(rtt_timing_data, 0, sizeof(rtt_timing_data));
	memset(iq_sample_channel_data, 0, sizeof(iq_sample_channel_data));

	bt_ras_rreq_rd_subevent_data_parse(peer_steps, local_steps, context.role, NULL,
					   process_step_data, &context);

	LOG_INF("Estimated distance to reflector:");

	float rtt_based_distance =
		estimate_distance_using_time_of_flight(context.rtt_timing_data_index);

	if (rtt_based_distance != 0.0f) {
		LOG_INF("- Round-Trip Timing method: %f meters (derived from %d samples)",
			(double)rtt_based_distance, context.rtt_timing_data_index);
		distance_measurement_failed = false;
	}
	for (int i = 0; i < n_ap; i++) {
		uint8_t samples_cnt = 0;
		float phase_slope_based_distance = estimate_distance_using_phase_slope(
			iq_sample_channel_data,
			context.iq_sample_channel_data_index,
			i,
			&samples_cnt);

		if (phase_slope_based_distance != 0.0f) {
			LOG_INF("- Phase-Based Ranging method: %f meters "
				"(derived on antenna path %d from %d samples)",
				(double)phase_slope_based_distance,
				i,
				samples_cnt);
			distance_measurement_failed = false;
		}
	}
	if (distance_measurement_failed) {
		LOG_INF("- A reliable distance estimate could not be computed.");
	}
}
```

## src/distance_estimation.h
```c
/*
 * Copyright (c) 2024 Nordic Semiconductor ASA
 *
 * SPDX-License-Identifier: LicenseRef-Nordic-5-Clause
 */

#include <stdint.h>
#include <zephyr/bluetooth/cs.h>

void estimate_distance(struct net_buf_simple *local_steps, struct net_buf_simple *peer_steps,
		       uint8_t n_ap, enum bt_conn_le_cs_role role);
```
